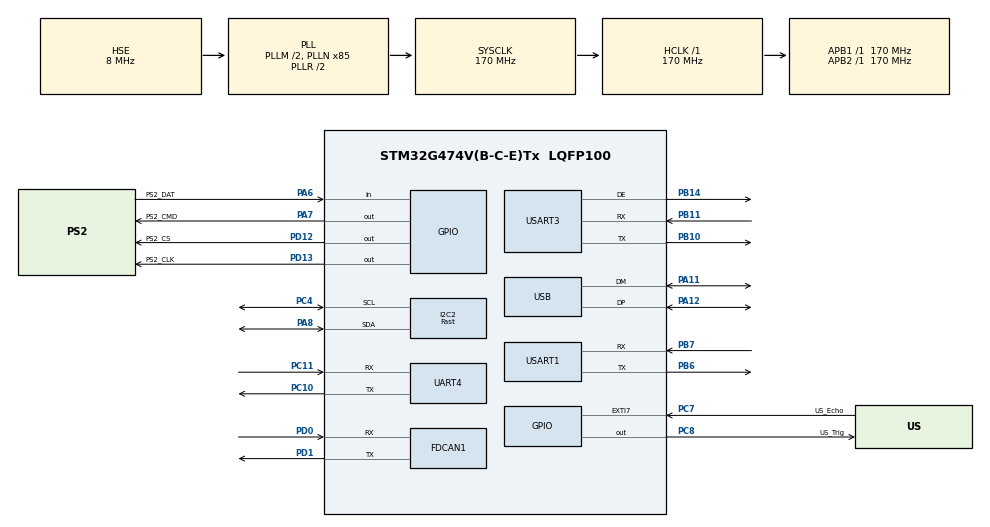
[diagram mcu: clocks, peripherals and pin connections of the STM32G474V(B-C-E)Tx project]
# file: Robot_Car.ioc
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Dma.I2C2_RX.6.Direction=DMA_PERIPH_TO_MEMORY
Dma.I2C2_RX.6.EventEnable=DISABLE
Dma.I2C2_RX.6.Instance=DMA1_Channel7
Dma.I2C2_RX.6.MemDataAlignment=DMA_MDATAALIGN_BYTE
Dma.I2C2_RX.6.MemInc=DMA_MINC_ENABLE
Dma.I2C2_RX.6.Mode=DMA_NORMAL
Dma.I2C2_RX.6.PeriphDataAlignment=DMA_PDATAALIGN_BYTE
Dma.I2C2_RX.6.PeriphInc=DMA_PINC_DISABLE
Dma.I2C2_RX.6.Polarity=HAL_DMAMUX_REQ_GEN_RISING
Dma.I2C2_RX.6.Priority=DMA_PRIORITY_MEDIUM
Dma.I2C2_RX.6.RequestNumber=1
Dma.I2C2_RX.6.SignalID=NONE
Dma.I2C2_RX.6.SyncEnable=DISABLE
Dma.I2C2_RX.6.SyncPolarity=HAL_DMAMUX_SYNC_NO_EVENT
Dma.I2C2_RX.6.SyncRequestNumber=1
Dma.I2C2_RX.6.SyncSignalID=NONE
Dma.I2C2_TX.7.Direction=DMA_MEMORY_TO_PERIPH
Dma.I2C2_TX.7.EventEnable=DISABLE
Dma.I2C2_TX.7.Instance=DMA1_Channel8
Dma.I2C2_TX.7.MemDataAlignment=DMA_MDATAALIGN_BYTE
Dma.I2C2_TX.7.MemInc=DMA_MINC_ENABLE
Dma.I2C2_TX.7.Mode=DMA_NORMAL
Dma.I2C2_TX.7.PeriphDataAlignment=DMA_PDATAALIGN_BYTE
Dma.I2C2_TX.7.PeriphInc=DMA_PINC_DISABLE
Dma.I2C2_TX.7.Polarity=HAL_DMAMUX_REQ_GEN_RISING
Dma.I2C2_TX.7.Priority=DMA_PRIORITY_MEDIUM
Dma.I2C2_TX.7.RequestNumber=1
Dma.I2C2_TX.7.SignalID=NONE
Dma.I2C2_TX.7.SyncEnable=DISABLE
Dma.I2C2_TX.7.SyncPolarity=HAL_DMAMUX_SYNC_NO_EVENT
Dma.I2C2_TX.7.SyncRequestNumber=1
Dma.I2C2_TX.7.SyncSignalID=NONE
Dma.Request0=UART4_RX
Dma.Request1=UART4_TX
Dma.Request2=USART1_RX
Dma.Request3=USART1_TX
Dma.Request4=USART3_RX
Dma.Request5=USART3_TX
Dma.Request6=I2C2_RX
Dma.Request7=I2C2_TX
Dma.UART4_RX.0.Direction=DMA_PERIPH_TO_MEMORY
Dma.UART4_RX.0.EventEnable=DISABLE
Dma.UART4_RX.0.Instance=DMA1_Channel1
Dma.UART4_RX.0.MemDataAlignment=DMA_MDATAALIGN_BYTE
Dma.UART4_RX.0.MemInc=DMA_MINC_ENABLE
Dma.UART4_RX.0.Mode=DMA_NORMAL
Dma.UART4_RX.0.PeriphDataAlignment=DMA_PDATAALIGN_BYTE
Dma.UART4_RX.0.PeriphInc=DMA_PINC_DISABLE
Dma.UART4_RX.0.Polarity=HAL_DMAMUX_REQ_GEN_RISING
Dma.UART4_RX.0.Priority=DMA_PRIORITY_HIGH
Dma.UART4_RX.0.RequestNumber=1
Dma.UART4_RX.0.SignalID=NONE
Dma.UART4_RX.0.SyncEnable=DISABLE
Dma.UART4_RX.0.SyncPolarity=HAL_DMAMUX_SYNC_NO_EVENT
Dma.UART4_RX.0.SyncRequestNumber=1
Dma.UART4_RX.0.SyncSignalID=NONE
Dma.UART4_TX.1.Direction=DMA_MEMORY_TO_PERIPH
Dma.UART4_TX.1.EventEnable=DISABLE
Dma.UART4_TX.1.Instance=DMA1_Channel2
Dma.UART4_TX.1.MemDataAlignment=DMA_MDATAALIGN_BYTE
Dma.UART4_TX.1.MemInc=DMA_MINC_ENABLE
Dma.UART4_TX.1.Mode=DMA_NORMAL
Dma.UART4_TX.1.PeriphDataAlignment=DMA_PDATAALIGN_BYTE
Dma.UART4_TX.1.PeriphInc=DMA_PINC_DISABLE
Dma.UART4_TX.1.Polarity=HAL_DMAMUX_REQ_GEN_RISING
Dma.UART4_TX.1.Priority=DMA_PRIORITY_LOW
Dma.UART4_TX.1.RequestNumber=1
Dma.UART4_TX.1.SignalID=NONE
Dma.UART4_TX.1.SyncEnable=DISABLE
Dma.UART4_TX.1.SyncPolarity=HAL_DMAMUX_SYNC_NO_EVENT
Dma.UART4_TX.1.SyncRequestNumber=1
Dma.UART4_TX.1.SyncSignalID=NONE
Dma.USART1_RX.2.Direction=DMA_PERIPH_TO_MEMORY
Dma.USART1_RX.2.EventEnable=DISABLE
Dma.USART1_RX.2.Instance=DMA1_Channel3
Dma.USART1_RX.2.MemDataAlignment=DMA_MDATAALIGN_BYTE
Dma.USART1_RX.2.MemInc=DMA_MINC_ENABLE
Dma.USART1_RX.2.Mode=DMA_NORMAL
Dma.USART1_RX.2.PeriphDataAlignment=DMA_PDATAALIGN_BYTE
Dma.USART1_RX.2.PeriphInc=DMA_PINC_DISABLE
Dma.USART1_RX.2.Polarity=HAL_DMAMUX_REQ_GEN_RISING
Dma.USART1_RX.2.Priority=DMA_PRIORITY_HIGH
Dma.USART1_RX.2.RequestNumber=1
Dma.USART1_RX.2.SignalID=NONE
Dma.USART1_RX.2.SyncEnable=DISABLE
Dma.USART1_RX.2.SyncPolarity=HAL_DMAMUX_SYNC_NO_EVENT
Dma.USART1_RX.2.SyncRequestNumber=1
Dma.USART1_RX.2.SyncSignalID=NONE
Dma.USART1_TX.3.Direction=DMA_MEMORY_TO_PERIPH
Dma.USART1_TX.3.EventEnable=DISABLE
Dma.USART1_TX.3.Instance=DMA1_Channel4
Dma.USART1_TX.3.MemDataAlignment=DMA_MDATAALIGN_BYTE
Dma.USART1_TX.3.MemInc=DMA_MINC_ENABLE
Dma.USART1_TX.3.Mode=DMA_NORMAL
Dma.USART1_TX.3.PeriphDataAlignment=DMA_PDATAALIGN_BYTE
Dma.USART1_TX.3.PeriphInc=DMA_PINC_DISABLE
Dma.USART1_TX.3.Polarity=HAL_DMAMUX_REQ_GEN_RISING
Dma.USART1_TX.3.Priority=DMA_PRIORITY_LOW
Dma.USART1_TX.3.RequestNumber=1
Dma.USART1_TX.3.SignalID=NONE
Dma.USART1_TX.3.SyncEnable=DISABLE
Dma.USART1_TX.3.SyncPolarity=HAL_DMAMUX_SYNC_NO_EVENT
Dma.USART1_TX.3.SyncRequestNumber=1
Dma.USART1_TX.3.SyncSignalID=NONE
Dma.USART3_RX.4.Direction=DMA_PERIPH_TO_MEMORY
Dma.USART3_RX.4.EventEnable=DISABLE
Dma.USART3_RX.4.Instance=DMA1_Channel5
Dma.USART3_RX.4.MemDataAlignment=DMA_MDATAALIGN_BYTE
Dma.USART3_RX.4.MemInc=DMA_MINC_ENABLE
Dma.USART3_RX.4.Mode=DMA_NORMAL
Dma.USART3_RX.4.PeriphDataAlignment=DMA_PDATAALIGN_BYTE
Dma.USART3_RX.4.PeriphInc=DMA_PINC_DISABLE
Dma.USART3_RX.4.Polarity=HAL_DMAMUX_REQ_GEN_RISING
Dma.USART3_RX.4.Priority=DMA_PRIORITY_HIGH
Dma.USART3_RX.4.RequestNumber=1
Dma.USART3_RX.4.SignalID=NONE
Dma.USART3_RX.4.SyncEnable=DISABLE
Dma.USART3_RX.4.SyncPolarity=HAL_DMAMUX_SYNC_NO_EVENT
Dma.USART3_RX.4.SyncRequestNumber=1
Dma.USART3_RX.4.SyncSignalID=NONE
Dma.USART3_TX.5.Direction=DMA_MEMORY_TO_PERIPH
Dma.USART3_TX.5.EventEnable=DISABLE
Dma.USART3_TX.5.Instance=DMA1_Channel6
Dma.USART3_TX.5.MemDataAlignment=DMA_MDATAALIGN_BYTE
Dma.USART3_TX.5.MemInc=DMA_MINC_ENABLE
Dma.USART3_TX.5.Mode=DMA_NORMAL
Dma.USART3_TX.5.PeriphDataAlignment=DMA_PDATAALIGN_BYTE
Dma.USART3_TX.5.PeriphInc=DMA_PINC_DISABLE
Dma.USART3_TX.5.Polarity=HAL_DMAMUX_REQ_GEN_RISING
Dma.USART3_TX.5.Priority=DMA_PRIORITY_LOW
Dma.USART3_TX.5.RequestNumber=1
Dma.USART3_TX.5.SignalID=NONE
Dma.USART3_TX.5.SyncEnable=DISABLE
Dma.USART3_TX.5.SyncPolarity=HAL_DMAMUX_SYNC_NO_EVENT
Dma.USART3_TX.5.SyncRequestNumber=1
Dma.USART3_TX.5.SyncSignalID=NONE
FDCAN1.CalculateBaudRateNominal=999999
FDCAN1.CalculateTimeBitNominal=1000
FDCAN1.CalculateTimeQuantumNominal=58.82352941176471
FDCAN1.NominalPrescaler=10
FDCAN1.NominalTimeSeg1=14
FDCAN1.NominalTimeSeg2=2
FDCAN1.StdFiltersNbr=1
FREERTOS.Tasks01=defaultTask,24,128,StartDefaultTask,Default,NULL,Dynamic,NULL,NULL
FREERTOS.configCHECK_FOR_STACK_OVERFLOW=2
FREERTOS.configENABLE_FPU=1
FREERTOS.configTOTAL_HEAP_SIZE=16384
I2C2.I2C_Speed_Mode=I2C_Fast
I2C2.Timing=0x40621236
Mcu.Family=STM32G4
Mcu.Name=STM32G474V(B-C-E)Tx
Mcu.Package=LQFP100
NVIC.DMA1_Channel1_IRQn=true\:5\:0\:false\:false\:true\:true\:false\:true\:true
NVIC.DMA1_Channel2_IRQn=true\:5\:0\:false\:false\:true\:true\:false\:true\:true
NVIC.DMA1_Channel3_IRQn=true\:5\:0\:false\:false\:true\:true\:false\:true\:true
NVIC.DMA1_Channel4_IRQn=true\:5\:0\:false\:false\:true\:true\:false\:true\:true
NVIC.DMA1_Channel5_IRQn=true\:5\:0\:false\:false\:true\:true\:false\:true\:true
NVIC.DMA1_Channel6_IRQn=true\:5\:0\:false\:false\:true\:true\:false\:true\:true
NVIC.DMA1_Channel7_IRQn=true\:5\:0\:false\:false\:true\:true\:false\:true\:true
NVIC.DMA1_Channel8_IRQn=true\:5\:0\:false\:false\:true\:true\:false\:true\:true
NVIC.EXTI9_5_IRQn=true\:5\:0\:false\:false\:true\:true\:true\:true\:true
NVIC.FDCAN1_IT0_IRQn=true\:5\:0\:true\:false\:true\:true\:true\:true\:true
NVIC.PriorityGroup=NVIC_PRIORITYGROUP_4
NVIC.TIM6_DAC_IRQn=true\:15\:0\:false\:false\:true\:false\:false\:true\:true
NVIC.TIM7_DAC_IRQn=true\:5\:0\:false\:false\:true\:true\:true\:true\:true
NVIC.TimeBase=TIM6_DAC_IRQn
NVIC.TimeBaseIP=TIM6
NVIC.UART4_IRQn=true\:5\:0\:true\:false\:true\:true\:true\:true\:true
NVIC.USART1_IRQn=true\:5\:0\:false\:false\:true\:true\:true\:true\:true
NVIC.USART3_IRQn=true\:5\:0\:true\:false\:true\:true\:false\:true\:true
NVIC.USB_LP_IRQn=true\:5\:0\:false\:false\:true\:true\:false\:true\:true
PA11.Mode=Device
PA11.Signal=USB_DM
PA12.Mode=Device
PA12.Signal=USB_DP
PA13.Mode=Serial_Wire
PA13.Signal=SYS_JTMS-SWDIO
PA14.Mode=Serial_Wire
PA14.Signal=SYS_JTCK-SWCLK
PA6.GPIO_Label=PS2_DAT
PA6.Signal=GPIO_Input
PA7.GPIO_Label=PS2_CMD
PA7.GPIO_Speed=GPIO_SPEED_FREQ_HIGH
PA7.PinState=GPIO_PIN_RESET
PA7.Signal=GPIO_Output
PA8.Mode=I2C
PA8.Signal=I2C2_SDA
PB10.Mode=Asynchronous
PB10.Signal=USART3_TX
PB11.Mode=Asynchronous
PB11.Signal=USART3_RX
PB14.Mode=Hardware Flow Control (RS485)
PB14.Signal=USART3_DE
PB6.Mode=Asynchronous
PB6.Signal=USART1_TX
PB7.Mode=Asynchronous
PB7.Signal=USART1_RX
PC10.Mode=Asynchronous
PC10.Signal=UART4_TX
PC11.Mode=Asynchronous
PC11.Signal=UART4_RX
PC14-OSC32_IN.Mode=LSE-External-Oscillator
PC14-OSC32_IN.Signal=RCC_OSC32_IN
PC15-OSC32_OUT.Mode=LSE-External-Oscillator
PC15-OSC32_OUT.Signal=RCC_OSC32_OUT
PC4.Mode=I2C
PC4.Signal=I2C2_SCL
PC7.GPIO_Label=US_Echo
PC7.GPIO_ModeDefaultEXTI=GPIO_MODE_IT_RISING_FALLING
PC7.Signal=GPXTI7
PC8.GPIO_Label=US_Trig
PC8.GPIO_Speed=GPIO_SPEED_FREQ_LOW
PC8.PinState=GPIO_PIN_SET
PC8.Signal=GPIO_Output
PD0.Mode=FDCAN_Activate
PD0.Signal=FDCAN1_RX
PD1.Mode=FDCAN_Activate
PD1.Signal=FDCAN1_TX
PD12.GPIO_Label=PS2_CS
PD12.GPIO_Speed=GPIO_SPEED_FREQ_HIGH
PD12.PinState=GPIO_PIN_SET
PD12.Signal=GPIO_Output
PD13.GPIO_Label=PS2_CLK
PD13.GPIO_Speed=GPIO_SPEED_FREQ_HIGH
PD13.PinState=GPIO_PIN_SET
PD13.Signal=GPIO_Output
PF0-OSC_IN.Mode=HSE-External-Oscillator
PF0-OSC_IN.Signal=RCC_OSC_IN
PF1-OSC_OUT.Mode=HSE-External-Oscillator
PF1-OSC_OUT.Signal=RCC_OSC_OUT
ProjectManager.HeapSize=0x200
ProjectManager.StackSize=0x400
ProjectManager.TargetToolchain=CMake
RCC.ADC12Freq_Value=170000000
RCC.ADC345Freq_Value=170000000
RCC.AHBFreq_Value=170000000
RCC.APB1Freq_Value=170000000
RCC.APB1TimFreq_Value=170000000
RCC.APB2Freq_Value=170000000
RCC.APB2TimFreq_Value=170000000
RCC.CK48CLockSelection=RCC_USBCLKSOURCE_HSI48
RCC.CortexFreq_Value=170000000
RCC.EXTERNAL_CLOCK_VALUE=12288000
RCC.HCLKFreq_Value=170000000
RCC.HSE_VALUE=8000000
RCC.HSI48_VALUE=48000000
RCC.HSI_VALUE=16000000
RCC.PLLM=RCC_PLLM_DIV2
RCC.PLLN=85
RCC.PLLSourceVirtual=RCC_PLLSOURCE_HSE
RCC.SYSCLKFreq_VALUE=170000000
RCC.SYSCLKSource=RCC_SYSCLKSOURCE_PLLCLK
RCC.USBFreq_Value=48000000
RCC.VCOOutputFreq_Value=340000000
TIM7.Prescaler=170-1
USART1.VirtualMode-Asynchronous=VM_ASYNC
USART3.VirtualMode-Asynchronous=VM_ASYNC
USART3.VirtualMode-Hardware\ Flow\ Control\ (RS485)=VM_ASYNC
USB_DEVICE.CLASS_NAME_FS=CDC
USB_DEVICE.VirtualMode=Cdc
USB_DEVICE.VirtualModeFS=Cdc_FS
VP_CORDIC_VS_CORDIC.Mode=CORDIC_Activate
VP_CRC_VS_CRC.Mode=CRC_Activate
VP_FMAC_VS_FMAC.Mode=FMAC_Activate
VP_FREERTOS_VS_CMSIS_V2.Mode=CMSIS_V2
VP_IWDG_VS_IWDG.Mode=IWDG_Activate
VP_RNG_VS_RNG.Mode=RNG_Activate
VP_RTC_VS_RTC_Activate.Mode=RTC_Enabled
VP_SYS_VS_DBSignals.Mode=DisableDeadBatterySignals
VP_SYS_VS_tim6.Mode=TIM6
VP_TIM7_VS_ClockSourceINT.Mode=Enable_Timer
VP_USB_DEVICE_VS_USB_DEVICE_CDC_FS.Mode=CDC_FS
board=custom

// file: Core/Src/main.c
/* USER CODE BEGIN Header */
/**
  ******************************************************************************
  * @file           : main.c
  * @brief          : Main program body
  ******************************************************************************
  * @attention
  *
  * Copyright (c) 2026 STMicroelectronics.
  * All rights reserved.
  *
  * This software is licensed under terms that can be found in the LICENSE file
  * in the root directory of this software component.
  * If no LICENSE file comes with this software, it is provided AS-IS.
  *
  ******************************************************************************
  */
/* USER CODE END Header */
#include "main.h"
#include "cmsis_os.h"
#include "cordic.h"
#include "crc.h"
#include "dma.h"
#include "fdcan.h"
#include "fmac.h"
#include "i2c.h"
#include "iwdg.h"
#include "rng.h"
#include "rtc.h"
#include "tim.h"
#include "usart.h"
#include "usb_device.h"
#include "gpio.h"

/* USER CODE BEGIN Includes */
#include "bsp_dwt.h"
/* USER CODE END Includes */

void SystemClock_Config(void);
void MX_FREERTOS_Init(void);

int main(void)
{

  /* MCU Configuration--------------------------------------------------------*/

  /* Reset of all peripherals, Initializes the Flash interface and the Systick. */
  HAL_Init();

  /* Configure the system clock */
  SystemClock_Config();

  /* Initialize all configured peripherals */
  MX_GPIO_Init();
  MX_DMA_Init();
  MX_I2C2_Init();
  MX_RTC_Init();
  MX_UART4_Init();
  MX_USART1_UART_Init();
  MX_USART3_UART_Init();
  MX_CORDIC_Init();
  MX_CRC_Init();
  MX_FDCAN1_Init();
  MX_FMAC_Init();
  MX_IWDG_Init();
  MX_RNG_Init();
  MX_TIM7_Init();

  /* Init scheduler */
  osKernelInitialize();  /* Call init function for freertos objects (in cmsis_os2.c) */
  MX_FREERTOS_Init();

  /* Start scheduler */
  osKernelStart();

  /* We should never get here as control is now taken by the scheduler */

  /* Infinite loop */
  while (1)
  {

  }
}

void SystemClock_Config(void)
{
  RCC_OscInitTypeDef RCC_OscInitStruct = {0};
  RCC_ClkInitTypeDef RCC_ClkInitStruct = {0};

  /** Configure the main internal regulator output voltage
  */
  HAL_PWREx_ControlVoltageScaling(PWR_REGULATOR_VOLTAGE_SCALE1_BOOST);

  /** Initializes the RCC Oscillators according to the specified parameters
  * in the RCC_OscInitTypeDef structure.
  */
  RCC_OscInitStruct.OscillatorType = RCC_OSCILLATORTYPE_HSI48|RCC_OSCILLATORTYPE_LSI
                              |RCC_OSCILLATORTYPE_HSE;
  RCC_OscInitStruct.HSEState = RCC_HSE_ON;
  RCC_OscInitStruct.LSIState = RCC_LSI_ON;
  RCC_OscInitStruct.HSI48State = RCC_HSI48_ON;
  RCC_OscInitStruct.PLL.PLLState = RCC_PLL_ON;
  RCC_OscInitStruct.PLL.PLLSource = RCC_PLLSOURCE_HSE;
  RCC_OscInitStruct.PLL.PLLM = RCC_PLLM_DIV2;
  RCC_OscInitStruct.PLL.PLLN = 85;
  RCC_OscInitStruct.PLL.PLLP = RCC_PLLP_DIV2;
  RCC_OscInitStruct.PLL.PLLQ = RCC_PLLQ_DIV2;
  RCC_OscInitStruct.PLL.PLLR = RCC_PLLR_DIV2;
  if (HAL_RCC_OscConfig(&RCC_OscInitStruct) != HAL_OK)
  {
    Error_Handler();
  }

  /** Initializes the CPU, AHB and APB buses clocks
  */
  RCC_ClkInitStruct.ClockType = RCC_CLOCKTYPE_HCLK|RCC_CLOCKTYPE_SYSCLK
                              |RCC_CLOCKTYPE_PCLK1|RCC_CLOCKTYPE_PCLK2;
  RCC_ClkInitStruct.SYSCLKSource = RCC_SYSCLKSOURCE_PLLCLK;
  RCC_ClkInitStruct.AHBCLKDivider = RCC_SYSCLK_DIV1;
  RCC_ClkInitStruct.APB1CLKDivider = RCC_HCLK_DIV1;
  RCC_ClkInitStruct.APB2CLKDivider = RCC_HCLK_DIV1;

  if (HAL_RCC_ClockConfig(&RCC_ClkInitStruct, FLASH_LATENCY_4) != HAL_OK)
  {
    Error_Handler();
  }
}

void HAL_TIM_PeriodElapsedCallback(TIM_HandleTypeDef *htim)
{
  if (htim->Instance == TIM6)
  {
    HAL_IncTick();
  }
}

void Error_Handler(void)
{
  __disable_irq();
  while (1)
  {
  }
}

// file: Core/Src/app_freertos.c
/* USER CODE BEGIN Header */
/**
  ******************************************************************************
  * File Name          : app_freertos.c
  * Description        : Code for freertos applications
  ******************************************************************************
  * @attention
  *
  * Copyright (c) 2026 STMicroelectronics.
  * All rights reserved.
  *
  * This software is licensed under terms that can be found in the LICENSE file
  * in the root directory of this software component.
  * If no LICENSE file comes with this software, it is provided AS-IS.
  *
  ******************************************************************************
  */
/* USER CODE END Header */

#include "FreeRTOS.h"
#include "task.h"
#include "main.h"
#include "cmsis_os.h"

#include "usb_device.h"

/* USER CODE BEGIN Includes */
#include "robot_task.h"
/* USER CODE END Includes */

/* Definitions for defaultTask */
osThreadId_t defaultTaskHandle;
const osThreadAttr_t defaultTask_attributes = {
  .name = "defaultTask",
  .priority = (osPriority_t) osPriorityNormal,
  .stack_size = 128 * 4
};

void StartDefaultTask(void *argument);

void MX_FREERTOS_Init(void); /* (MISRA C 2004 rule 8.1) */

/* Hook prototypes */
void vApplicationStackOverflowHook(xTaskHandle xTask, signed char *pcTaskName);

/* USER CODE BEGIN 4 */
void vApplicationStackOverflowHook(xTaskHandle xTask, signed char *pcTaskName)
{
   /* Run time stack overflow checking is performed if
   configCHECK_FOR_STACK_OVERFLOW is defined to 1 or 2. This hook function is
   called if a stack overflow is detected. */
}
/* USER CODE END 4 */

void MX_FREERTOS_Init(void) {

  /* Create the thread(s) */
  /* creation of defaultTask */
  defaultTaskHandle = osThreadNew(StartDefaultTask, NULL, &defaultTask_attributes);

  /* USER CODE BEGIN RTOS_THREADS */
  /* add threads, ... */
  Robot_task_init();
  /* USER CODE END RTOS_THREADS */

}

void StartDefaultTask(void *argument)
{
  /* init code for USB_Device */
  MX_USB_Device_Init();
  for(;;)
  {
    osDelay(1);
  }
}
